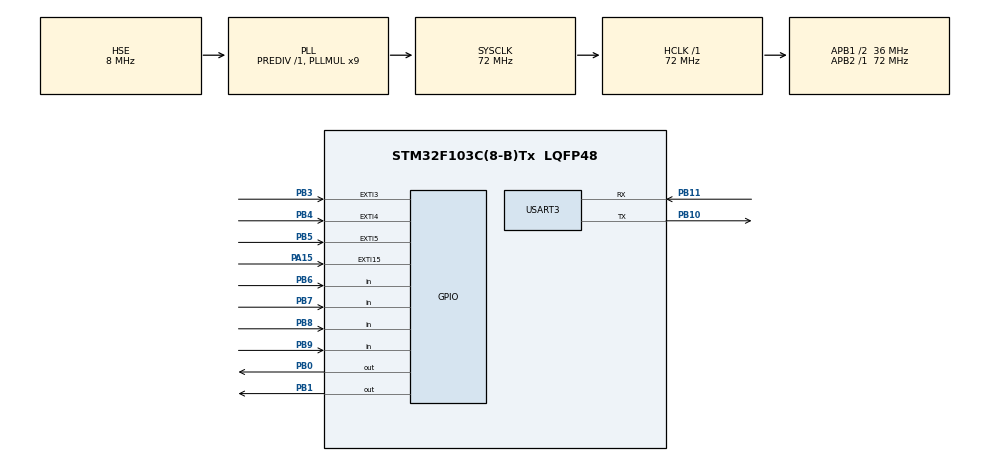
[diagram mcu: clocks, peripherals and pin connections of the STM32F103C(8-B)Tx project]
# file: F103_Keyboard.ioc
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Mcu.Family=STM32F1
PB7.GPIO_PuPd=GPIO_PULLDOWN
RCC.PLLSourceVirtual=RCC_PLLSOURCE_HSE
NVIC.EXTI4_IRQn=true\:3\:0\:true\:false\:true\:true\:true
PD1-OSC_OUT.Mode=HSE-External-Oscillator
PB10.Mode=Asynchronous
PB4.GPIO_ModeDefaultEXTI=GPIO_MODE_IT_FALLING
PB6.GPIO_PuPd=GPIO_PULLDOWN
PB8.GPIO_PuPd=GPIO_PULLDOWN
NVIC.EXTI3_IRQn=true\:3\:0\:true\:false\:true\:true\:true
PD0-OSC_IN.Signal=RCC_OSC_IN
PB3.GPIO_ModeDefaultEXTI=GPIO_MODE_IT_FALLING
RCC.APB1CLKDivider=RCC_HCLK_DIV2
PB11.Signal=USART3_RX
RCC.SYSCLKSource=RCC_SYSCLKSOURCE_PLLCLK
ProjectManager.StackSize=0x400
PD1-OSC_OUT.Signal=RCC_OSC_OUT
PA13.Signal=SYS_JTMS-SWDIO
PB11.Mode=Asynchronous
ProjectManager.TargetToolchain=STM32CubeIDE
PA15.GPIO_ModeDefaultEXTI=GPIO_MODE_IT_FALLING
PB1.GPIO_PuPd=GPIO_PULLUP
RCC.HCLKFreq_Value=72000000
RCC.APB2TimFreq_Value=72000000
PB6.Signal=GPIO_Input
PB4.GPIO_PuPd=GPIO_PULLUP
RCC.USBFreq_Value=72000000
RCC.AHBFreq_Value=72000000
PD0-OSC_IN.Mode=HSE-External-Oscillator
PB10.Signal=USART3_TX
NVIC.EXTI15_10_IRQn=true\:3\:0\:true\:false\:true\:true\:true
board=custom
RCC.PLLMUL=RCC_PLL_MUL9
RCC.APB2Freq_Value=72000000
PB3.GPIO_PuPd=GPIO_PULLUP
PA14.Mode=Serial_Wire
PB7.Signal=GPIO_Input
PA13.Mode=Serial_Wire
Mcu.Name=STM32F103C(8-B)Tx
PB3.Signal=GPXTI3
RCC.SYSCLKFreq_VALUE=72000000
Mcu.Package=LQFP48
PB5.Signal=GPXTI5
PB9.Signal=GPIO_Input
PB1.Signal=GPIO_Output
USART3.VirtualMode=VM_ASYNC
PB5.GPIO_PuPd=GPIO_PULLUP
NVIC.EXTI9_5_IRQn=true\:3\:0\:true\:false\:true\:true\:true
PA14.Signal=SYS_JTCK-SWCLK
PB9.GPIO_PuPd=GPIO_PULLDOWN
PA15.Signal=GPXTI15
ProjectManager.HeapSize=0x200
NVIC.PriorityGroup=NVIC_PRIORITYGROUP_4
PA15.GPIO_PuPd=GPIO_PULLUP
RCC.APB1TimFreq_Value=72000000
PB8.Signal=GPIO_Input
RCC.APB1Freq_Value=36000000
PB0.Signal=GPIO_Output
PB0.GPIO_PuPd=GPIO_PULLUP
PB4.Signal=GPXTI4
PB5.GPIO_ModeDefaultEXTI=GPIO_MODE_IT_FALLING

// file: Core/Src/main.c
/* USER CODE BEGIN Header */
/**
  ******************************************************************************
  * @file           : main.c
  * @brief          : Main program body
  ******************************************************************************
  * @attention
  *
  * <h2><center>&copy; Copyright (c) 2021 STMicroelectronics.
  * All rights reserved.</center></h2>
  *
  * This software component is licensed by ST under BSD 3-Clause license,
  * the "License"; You may not use this file except in compliance with the
  * License. You may obtain a copy of the License at:
  *                        opensource.org/licenses/BSD-3-Clause
  *
  ******************************************************************************
  */
/* USER CODE END Header */
#include "main.h"
#include "usart.h"
#include "gpio.h"

/* USER CODE BEGIN Includes */
#include <stdio.h>
#include "oled.h"
/* USER CODE END Includes */

void SystemClock_Config(void);

int main(void)
{
  /* USER CODE BEGIN 1 */
	char keyCh = 0;
  /* USER CODE END 1 */

  /* MCU Configuration--------------------------------------------------------*/

  /* Reset of all peripherals, Initializes the Flash interface and the Systick. */
  HAL_Init();

  /* Configure the system clock */
  SystemClock_Config();

  /* Initialize all configured peripherals */
  MX_GPIO_Init();
  MX_USART3_UART_Init();
  /* USER CODE BEGIN 2 */
  printf("F103 KEY Board demo\r\n");

  OLED_Init();
  OLED_DrawLogo();
  OLED_Show_MyBilibili();
  HAL_Delay(1000);
  OLED_Clear();
  /* USER CODE END 2 */

  /* Infinite loop */
  while (1)
  {

    /* USER CODE BEGIN 3 */
	  keyCh = Get_Key_Ch();
	  if(0 != keyCh){
		  printf("keyCh:%c\r\n", keyCh);
		  OLED_ShowChar(60, 3, keyCh, 16);
	  }
  }
  /* USER CODE END 3 */
}

void SystemClock_Config(void)
{
  RCC_OscInitTypeDef RCC_OscInitStruct = {0};
  RCC_ClkInitTypeDef RCC_ClkInitStruct = {0};

  /** Initializes the RCC Oscillators according to the specified parameters
  * in the RCC_OscInitTypeDef structure.
  */
  RCC_OscInitStruct.OscillatorType = RCC_OSCILLATORTYPE_HSE;
  RCC_OscInitStruct.HSEState = RCC_HSE_ON;
  RCC_OscInitStruct.HSEPredivValue = RCC_HSE_PREDIV_DIV1;
  RCC_OscInitStruct.HSIState = RCC_HSI_ON;
  RCC_OscInitStruct.PLL.PLLState = RCC_PLL_ON;
  RCC_OscInitStruct.PLL.PLLSource = RCC_PLLSOURCE_HSE;
  RCC_OscInitStruct.PLL.PLLMUL = RCC_PLL_MUL9;
  if (HAL_RCC_OscConfig(&RCC_OscInitStruct) != HAL_OK)
  {
    Error_Handler();
  }
  /** Initializes the CPU, AHB and APB buses clocks
  */
  RCC_ClkInitStruct.ClockType = RCC_CLOCKTYPE_HCLK|RCC_CLOCKTYPE_SYSCLK
                              |RCC_CLOCKTYPE_PCLK1|RCC_CLOCKTYPE_PCLK2;
  RCC_ClkInitStruct.SYSCLKSource = RCC_SYSCLKSOURCE_PLLCLK;
  RCC_ClkInitStruct.AHBCLKDivider = RCC_SYSCLK_DIV1;
  RCC_ClkInitStruct.APB1CLKDivider = RCC_HCLK_DIV2;
  RCC_ClkInitStruct.APB2CLKDivider = RCC_HCLK_DIV1;

  if (HAL_RCC_ClockConfig(&RCC_ClkInitStruct, FLASH_LATENCY_2) != HAL_OK)
  {
    Error_Handler();
  }
}

void Error_Handler(void)
{
  __disable_irq();
  while (1)
  {
  }
}

/************************ (C) COPYRIGHT STMicroelectronics *****END OF FILE****/
